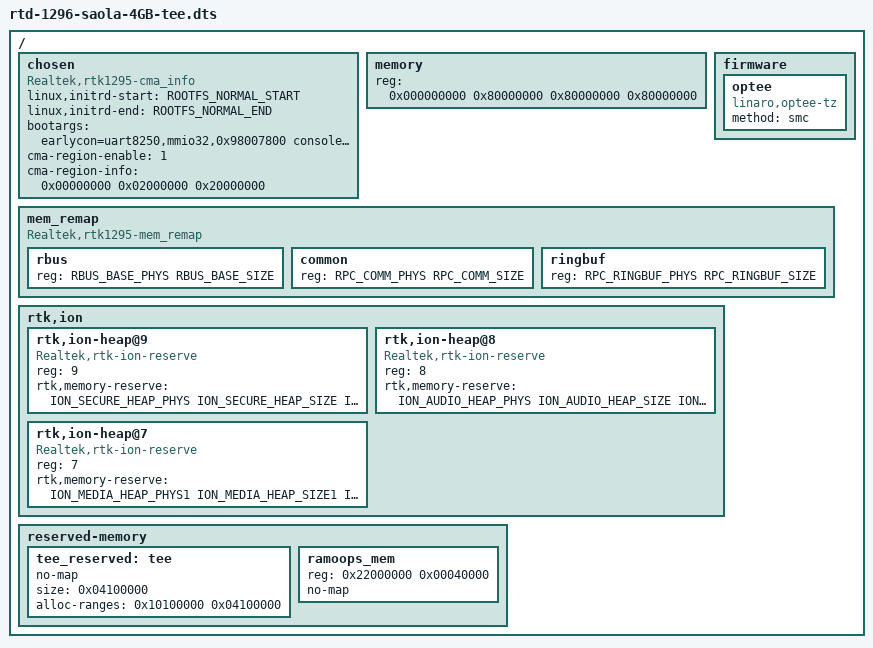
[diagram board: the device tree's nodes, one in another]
/dts-v1/;
#include "../../../../../include/soc/realtek/memory.h"

/memreserve/ SYS_BOOTCODE_MEMBASE       SYS_BOOTCODE_MEMSIZE        ; /* 0x00000000 ~ 0x0002ffff */
/memreserve/ RPC_COMM_PHYS              RPC_COMM_SIZE               ; /* 0x0001f000 ~ 0x0001ffff */
/memreserve/ RPC_RINGBUF_PHYS           RPC_RINGBUF_SIZE            ; /* 0x01ffe000 ~ 0x02001fff */
/memreserve/ ROOTFS_NORMAL_START        ROOTFS_NORMAL_SIZE          ; /* 0x02200000 ~ 0x025fffff */
/memreserve/ ACPU_IDMEM_PHYS            ACPU_IDMEM_SIZE             ; /* 0x10000000 ~ 0x10013fff */
/memreserve/ 0x10100000                 0x04100000                  ; /* 0x10100000 ~ 0x141fffff */

#include "rtd-129x-ion-2GB-tee.dtsi"
#include "rtd-1296.dtsi"
#include "rtd-129x-dvfs.dtsi"
#include "rtd-1296-saola-common.dtsi"

/ {
	chosen {
        linux,initrd-start = <ROOTFS_NORMAL_START>;
        linux,initrd-end = <ROOTFS_NORMAL_END>;
        bootargs = "earlycon=uart8250,mmio32,0x98007800 console=ttyS0,115200 init=/init androidboot.hardware=kylin androidboot.storage=emmc loglevel=4";
	};

	chosen {
        compatible = "Realtek,rtk1295-cma_info";
        /* NOTE ---------------------------------------------------------------------------------------------*/
        /* <flag size base>                                                                                  */
        /* flag: reserved                                                                                    */
        /* size: unit is byte                                                                                */
        /* base: unit is byte                                                                                */
        /* --------------------------------------------------------------------------------------------------*/
        /* Array size not over 8;                                                                            */
        /* You may change the max array size in KConfig, max CMA array size is CONFIG_CMA_AREAS+1            */
        /* If cma-region-enable is enabled<1>, kernel driver will use cma-region-info to initial CMA memory. */
        /* If cma-region-enable is disabled<0>, kernel driver will use cma= to initial CMA memory.           */
        /* if both setting is loaded, cma-region-info had higher priority.                                   */
        /* --------------------------------------------------------------------------------------------------*/
        cma-region-enable = <1>;
        cma-region-info = <0x00000000 0x02000000 0x20000000>;
        /*cma-region-info = <0x00000000 0x01000000 0x12c00000>, <0x00000000 0x12c00000 0x20000000>;*/
	};

    memory {
        device_type = "memory";
        reg = <0x000000000 0x80000000 0x80000000 0x80000000>; /* 4096 MB */
    };
    firmware {
      optee {
        compatible = "linaro,optee-tz";
        method = "smc";
      };
    };
    mem_remap {
        compatible = "Realtek,rtk1295-mem_remap";
        #address-cells = <1>;
        #size-cells = <1>;
        ranges;
        rbus {
            reg = <RBUS_BASE_PHYS RBUS_BASE_SIZE>;
        };
        common {
            reg = <RPC_COMM_PHYS RPC_COMM_SIZE>;
        };
        ringbuf {
            reg = <RPC_RINGBUF_PHYS RPC_RINGBUF_SIZE>;
        };
    };

    rtk,ion {
        rtk,ion-heap@9 {    /* Secure */
            compatible = "Realtek,rtk-ion-reserve";
            reg = <9>;
            rtk,memory-reserve = <
                ION_SECURE_HEAP_PHYS ION_SECURE_HEAP_SIZE ION_SECURE_HEAP_FLAG
                >;
        };
        rtk,ion-heap@8 {    /* Audio */
            compatible = "Realtek,rtk-ion-reserve";
            reg = <8>;
            rtk,memory-reserve = <
                ION_AUDIO_HEAP_PHYS ION_AUDIO_HEAP_SIZE ION_AUDIO_HEAP_FLAG
                >;
        };
        rtk,ion-heap@7 {    /* TYPE_MEDIA */
            compatible = "Realtek,rtk-ion-reserve";
            reg = <7>;
            rtk,memory-reserve = <
                ION_MEDIA_HEAP_PHYS1 ION_MEDIA_HEAP_SIZE1 ION_MEDIA_HEAP_FLAG1
                ION_MEDIA_HEAP_PHYS2 ION_MEDIA_HEAP_SIZE2 ION_MEDIA_HEAP_FLAG2
                ION_MEDIA_HEAP_PHYS3 ION_MEDIA_HEAP_SIZE3 ION_MEDIA_HEAP_FLAG3
                >;
        };
    };
    reserved-memory {
        #address-cells = <1>;
        #size-cells = <1>;
        ranges;

        tee_reserved: tee {
            no-map;
            size = <0x04100000>;
            alloc-ranges = <0x10100000 0x04100000>;
        };  
        ramoops_mem: ramoops_mem {
            reg = <0x22000000 0x00040000>;
            reg-names = "ramoops_mem";
            no-map;
        };
    };
};
